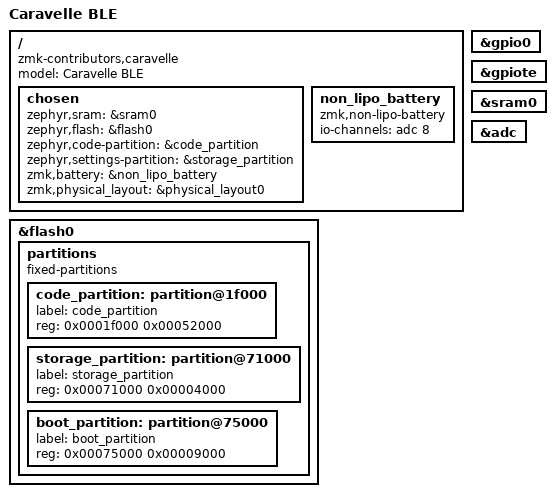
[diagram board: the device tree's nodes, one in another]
/* Minimal board DTS for Caravelle to allow devicetree preprocessing in CI.
 * Add peripherals/back references as needed later. */
/dts-v1/;
#include <nordic/nrf52832_qfaa.dtsi>
#include <dt-bindings/zmk/matrix_transform.h>

/ {
	model = "Caravelle BLE";
	compatible = "zmk-contributors,caravelle";

	chosen {
		zephyr,sram = &sram0;
		zephyr,flash = &flash0;
        zephyr,code-partition = &code_partition;
        zephyr,settings-partition = &storage_partition;
        zmk,battery = &non_lipo_battery;
        zmk,physical_layout = &physical_layout0;
	};

    non_lipo_battery: non_lipo_battery {
        compatible = "zmk,non-lipo-battery";
        io-channels = <&adc 8>;  // vdd
    }; 
};

&gpio0 {
	status = "okay";
};

&gpiote {
	status = "okay";
};

&flash0 {
    partitions {
        compatible = "fixed-partitions";
        #address-cells = <1>;
        #size-cells = <1>;

        /* 0x00000 - 0x1F000 (124KB): SoftDevice S132 v3.0 */

        /* 0x1F000 - 0x71000 (328KB): ZMK Application */
        code_partition: partition@1f000 {
            label = "code_partition";
            reg = <0x0001f000 0x00052000>;
        };

        /* 0x71000 - 0x75000 (16KB): ZMK Storage / NVS */
        storage_partition: partition@71000 {
            label = "storage_partition";
            reg = <0x00071000 0x00004000>;
        };

        /* 0x75000 - 0x7E000 (36KB): Nordic Secure DFU Bootloader */
        boot_partition: partition@75000 {
            label = "boot_partition";
            reg = <0x00075000 0x00009000>;
        };
    };
};


&sram0 {
	status = "okay";
};

&adc {
	status ="okay";
};
